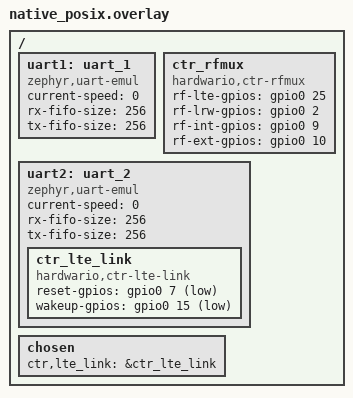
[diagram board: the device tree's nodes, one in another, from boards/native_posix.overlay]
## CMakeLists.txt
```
cmake_minimum_required(VERSION 3.20.0)

find_package(Zephyr REQUIRED HINTS $ENV{ZEPHYR_BASE})
project(test)

add_compile_definitions(CONFIG_CTR_RFMUX_LOG_LEVEL=4)
add_compile_definitions(CONFIG_CTR_LTE_LINK_LOG_LEVEL=3)

include_directories(${CMAKE_CURRENT_SOURCE_DIR}/../../../subsys/ctr_lte_v2)

target_sources(app PRIVATE src/mock_ctr_rfmux.c)
target_sources(app PRIVATE src/mock_ctr_lte_link.c)
target_sources(app PRIVATE src/mock_ctr_rtc.c)
target_sources(app PRIVATE src/mock_ctr_info.c)

target_sources_ifdef(CONFIG_TEST_FEATURE_PARSING app PRIVATE src/test_parse.c)
target_sources_ifdef(CONFIG_TEST_FEATURE_PARSING app PRIVATE src/test_state.c)
target_sources_ifdef(CONFIG_TEST_FEATURE_PARSING app PRIVATE src/test_str.c)
target_sources_ifdef(CONFIG_TEST_FEATURE_PARSING app PRIVATE src/test_fmt_duration.c)

if(CONFIG_TEST_FEATURE_PARSING AND CONFIG_CTR_LTE_V2_SCAN)
  target_sources(app PRIVATE src/test_parse_scan.c)
endif()

target_sources_ifdef(CONFIG_TEST_FEATURE_STACK app PRIVATE src/test_stack.c)
target_sources_ifdef(CONFIG_TEST_FEATURE_TXN app PRIVATE src/test_txn.c)
target_sources_ifdef(CONFIG_TEST_FEATURE_SCAN app PRIVATE src/test_scan.c)

if(CONFIG_TEST_FEATURE_STACK OR CONFIG_TEST_FEATURE_TXN OR CONFIG_TEST_FEATURE_SCAN)
  target_sources(app PRIVATE src/stack.c)
endif()

# The 'lte' shell commands, without CONFIG_CTR_SHELL (it selects the RTT backend)
if(CONFIG_TEST_FEATURE_TXN OR CONFIG_TEST_FEATURE_SCAN)
  target_sources(app PRIVATE ${CMAKE_CURRENT_SOURCE_DIR}/../../../subsys/ctr_lte_v2/ctr_lte_v2_shell.c)
endif()
```

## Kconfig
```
#
# Copyright (c) 2023 HARDWARIO a.s.
#
# SPDX-License-Identifier: LicenseRef-HARDWARIO-5-Clause
#

menu "Test Features"

config TEST_FEATURE_PARSING
	bool "TEST_FEATURE_PARSING"
	default n

config TEST_FEATURE_STACK
	bool "TEST_FEATURE_PARSING"
	default n
	select CTR_LTE_V2_GNSS

config TEST_FEATURE_STACK_OVERRIDES_CONFIG
	bool "TEST_FEATURE_STACK"
	default n
	select CTR_LTE_V2_GNSS
	select TEST_FEATURE_STACK

config TEST_FEATURE_STACK_FPLMN_ERASE_FAILS
	bool "TEST_FEATURE_STACK_FPLMN_ERASE_FAILS"
	default n
	select TEST_FEATURE_STACK
	help
	  The SIM holds forbidden networks and refuses to erase them; the
	  attach must go on anyway.

config TEST_FEATURE_TXN
	bool "TEST_FEATURE_TXN"
	default n
	select CTR_LTE_V2_GNSS
	help
	  A send_recv transaction scenario; each runs in a configuration of its
	  own.

config TEST_FEATURE_TXN_GIVE_UP_IN_RECV
	bool "TEST_FEATURE_TXN_GIVE_UP_IN_RECV"
	select TEST_FEATURE_TXN

config TEST_FEATURE_TXN_GIVE_UP_IN_ATTACH
	bool "TEST_FEATURE_TXN_GIVE_UP_IN_ATTACH"
	select TEST_FEATURE_TXN

config TEST_FEATURE_TXN_GIVE_UP_IN_ERROR
	bool "TEST_FEATURE_TXN_GIVE_UP_IN_ERROR"
	select TEST_FEATURE_TXN

config TEST_FEATURE_TXN_GIVE_UP_IN_SEND
	bool "TEST_FEATURE_TXN_GIVE_UP_IN_SEND"
	select TEST_FEATURE_TXN

config TEST_FEATURE_TXN_GIVE_UP_IN_XSEND
	bool "TEST_FEATURE_TXN_GIVE_UP_IN_XSEND"
	select TEST_FEATURE_TXN

config TEST_FEATURE_TXN_LOCK_BUSY
	bool "TEST_FEATURE_TXN_LOCK_BUSY"
	select TEST_FEATURE_TXN

config TEST_FEATURE_TXN_CSCON_AGAIN_IN_RECV
	bool "TEST_FEATURE_TXN_CSCON_AGAIN_IN_RECV"
	select TEST_FEATURE_TXN

config TEST_FEATURE_TXN_CSCON_1_0_IN_SEND
	bool "TEST_FEATURE_TXN_CSCON_1_0_IN_SEND"
	select TEST_FEATURE_TXN

config TEST_FEATURE_TXN_RECONNECT_IN_RECV
	bool "TEST_FEATURE_TXN_RECONNECT_IN_RECV"
	select TEST_FEATURE_TXN

config TEST_FEATURE_TXN_RECONNECT_IN_ERROR
	bool "TEST_FEATURE_TXN_RECONNECT_IN_ERROR"
	select TEST_FEATURE_TXN

config TEST_FEATURE_TXN_RECV_NO_DATA
	bool "TEST_FEATURE_TXN_RECV_NO_DATA"
	select TEST_FEATURE_TXN

config TEST_FEATURE_TXN_RECV_FAIL
	bool "TEST_FEATURE_TXN_RECV_FAIL"
	select TEST_FEATURE_TXN

config TEST_FEATURE_TXN_ERROR_NO_SOCKET
	bool "TEST_FEATURE_TXN_ERROR_NO_SOCKET"
	select TEST_FEATURE_TXN

config TEST_FEATURE_TXN_DISABLED
	bool "TEST_FEATURE_TXN_DISABLED"
	select TEST_FEATURE_TXN

config TEST_FEATURE_TXN_NO_CSCON
	bool "TEST_FEATURE_TXN_NO_CSCON"
	select TEST_FEATURE_TXN

config TEST_FEATURE_TXN_CSCON_TIMER
	bool "TEST_FEATURE_TXN_CSCON_TIMER"
	select TEST_FEATURE_TXN

config TEST_FEATURE_TXN_CSCON_0_IN_SEND
	bool "TEST_FEATURE_TXN_CSCON_0_IN_SEND"
	select TEST_FEATURE_TXN

config TEST_FEATURE_TXN_ERROR_IN_SEND
	bool "TEST_FEATURE_TXN_ERROR_IN_SEND"
	select TEST_FEATURE_TXN

config TEST_FEATURE_TXN_REATTACH_IN_SEND
	bool "TEST_FEATURE_TXN_REATTACH_IN_SEND"
	select TEST_FEATURE_TXN

config TEST_FEATURE_TXN_DEREGISTERED_IN_READY
	bool "TEST_FEATURE_TXN_DEREGISTERED_IN_READY"
	select TEST_FEATURE_TXN

config TEST_FEATURE_TXN_CALLBACKS
	bool "TEST_FEATURE_TXN_CALLBACKS"
	select TEST_FEATURE_TXN

config TEST_FEATURE_TXN_NO_PSM_CFUN4
	bool "TEST_FEATURE_TXN_NO_PSM_CFUN4"
	select TEST_FEATURE_TXN

config TEST_FEATURE_SCAN
	bool "TEST_FEATURE_SCAN"
	default n
	select CTR_LTE_V2_SCAN
	select CTR_LTE_V2_GNSS
	help
	  A scenario of the neighbour cell measurement or of the network scan;
	  each runs in a configuration of its own.

config TEST_FEATURE_SCAN_NCELLMEAS
	bool "TEST_FEATURE_SCAN_NCELLMEAS"
	select TEST_FEATURE_SCAN

config TEST_FEATURE_SCAN_NCELLMEAS_FAIL
	bool "TEST_FEATURE_SCAN_NCELLMEAS_FAIL"
	select TEST_FEATURE_SCAN

config TEST_FEATURE_SCAN_NCELLMEAS_NO_PSM
	bool "TEST_FEATURE_SCAN_NCELLMEAS_NO_PSM"
	select TEST_FEATURE_SCAN

config TEST_FEATURE_SCAN_NCELLMEAS_FROM_SLEEP
	bool "TEST_FEATURE_SCAN_NCELLMEAS_FROM_SLEEP"
	select TEST_FEATURE_SCAN

config TEST_FEATURE_SCAN_NCELLMEAS_CANCEL
	bool "TEST_FEATURE_SCAN_NCELLMEAS_CANCEL"
	select TEST_FEATURE_SCAN

config TEST_FEATURE_SCAN_LTE_M
	bool
	help
	  The scan runs in LTE-M only ('lte config mode lte-m', as the U1).

config TEST_FEATURE_SCAN_NB_IOT
	bool
	help
	  The scan runs in NB-IoT only ('lte config mode nb-iot', as the board with PSM).

config TEST_FEATURE_SCAN_SCAN_BOTH
	bool "TEST_FEATURE_SCAN_SCAN_BOTH"
	select TEST_FEATURE_SCAN

config TEST_FEATURE_SCAN_SCAN_ONE_RAT
	bool "TEST_FEATURE_SCAN_SCAN_ONE_RAT"
	select TEST_FEATURE_SCAN
	select TEST_FEATURE_SCAN_LTE_M

config TEST_FEATURE_SCAN_SCAN_TIMEOUTS
	bool "TEST_FEATURE_SCAN_SCAN_TIMEOUTS"
	select TEST_FEATURE_SCAN
	select TEST_FEATURE_SCAN_LTE_M

config TEST_FEATURE_SCAN_SCAN_COPS_TIMEOUT
	bool "TEST_FEATURE_SCAN_SCAN_COPS_TIMEOUT"
	select TEST_FEATURE_SCAN

config TEST_FEATURE_SCAN_SCAN_COPS_CME
	bool "TEST_FEATURE_SCAN_SCAN_COPS_CME"
	select TEST_FEATURE_SCAN

config TEST_FEATURE_SCAN_SCAN_STEP_FAIL
	bool "TEST_FEATURE_SCAN_SCAN_STEP_FAIL"
	select TEST_FEATURE_SCAN

config TEST_FEATURE_SCAN_SCAN_SEND
	bool "TEST_FEATURE_SCAN_SCAN_SEND"
	select TEST_FEATURE_SCAN
	select TEST_FEATURE_SCAN_NB_IOT

config TEST_FEATURE_SCAN_SCAN_SEND_CFUN4
	bool "TEST_FEATURE_SCAN_SCAN_SEND_CFUN4"
	select TEST_FEATURE_SCAN
	select TEST_FEATURE_SCAN_LTE_M

config TEST_FEATURE_SCAN_SCAN_SEND_AFTER
	bool "TEST_FEATURE_SCAN_SCAN_SEND_AFTER"
	select TEST_FEATURE_SCAN
	select TEST_FEATURE_SCAN_LTE_M

config TEST_FEATURE_SCAN_SCAN_RECONNECT
	bool "TEST_FEATURE_SCAN_SCAN_RECONNECT"
	select TEST_FEATURE_SCAN

config TEST_FEATURE_SCAN_SCAN_IN_ATTACH
	bool "TEST_FEATURE_SCAN_SCAN_IN_ATTACH"
	select TEST_FEATURE_SCAN
	select TEST_FEATURE_SCAN_LTE_M

config TEST_FEATURE_SCAN_SCAN_IN_RETRY_DELAY
	bool "TEST_FEATURE_SCAN_SCAN_IN_RETRY_DELAY"
	select TEST_FEATURE_SCAN
	select TEST_FEATURE_SCAN_NB_IOT

config TEST_FEATURE_SCAN_SCAN_IN_GNSS
	bool "TEST_FEATURE_SCAN_SCAN_IN_GNSS"
	select TEST_FEATURE_SCAN
	select TEST_FEATURE_SCAN_NB_IOT

config TEST_FEATURE_SCAN_SCAN_IN_GNSS_NO_PSM
	bool "TEST_FEATURE_SCAN_SCAN_IN_GNSS_NO_PSM"
	select TEST_FEATURE_SCAN
	select TEST_FEATURE_SCAN_LTE_M

config TEST_FEATURE_SCAN_SCAN_RESET_LOOP
	bool "TEST_FEATURE_SCAN_SCAN_RESET_LOOP"
	select TEST_FEATURE_SCAN
	select TEST_FEATURE_SCAN_LTE_M

config TEST_FEATURE_SCAN_SCAN_MODES
	bool "TEST_FEATURE_SCAN_SCAN_MODES"
	select TEST_FEATURE_SCAN

config CTR_LTE_V2_DEFAULT_MODE
	string "LTE Mode for CTR_LTE_V2"
	default "lte-m" if TEST_FEATURE_SCAN_LTE_M
	default "nb-iot" if TEST_FEATURE_SCAN_NB_IOT

config CTR_LTE_V2_DEFAULT_BANDS
	string "LTE Bands for CTR_LTE_V2"
	default "2,4,5,8,12,13,17,18,19,20,25,26,28,66" if TEST_FEATURE_STACK_OVERRIDES_CONFIG

config CTR_LTE_V2_DEFAULT_NETWORK
	string "Default Network for CTR_LTE_V2"
	default "23003" if TEST_FEATURE_STACK_OVERRIDES_CONFIG

config CTR_LTE_V2_DEFAULT_APN
	string "Default APN for CTR_LTE_V2"
	default "hardwario" if TEST_FEATURE_STACK_OVERRIDES_CONFIG

config CTR_LTE_V2_DEFAULT_ADDR
	string "Default Address for CTR_LTE_V2"
	default "46.101.214.168" if TEST_FEATURE_STACK_OVERRIDES_CONFIG

endmenu

#Include Zephyr's Kconfig
source "Kconfig"
```

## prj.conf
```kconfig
CONFIG_ZTEST=y
CONFIG_HEAP_MEM_POOL_SIZE=256
CONFIG_MAIN_STACK_SIZE=2048

CONFIG_LOG=y
CONFIG_LOG_FUNC_NAME_PREFIX_ERR=y
CONFIG_LOG_FUNC_NAME_PREFIX_WRN=y
CONFIG_LOG_FUNC_NAME_PREFIX_INF=y
CONFIG_LOG_FUNC_NAME_PREFIX_DBG=y

CONFIG_EVENTS=y

CONFIG_CTR_BUF=y
CONFIG_CTR_UTIL=y
CONFIG_CTR_CONFIG=y

CONFIG_CTR_LTE_V2=y
CONFIG_CTR_LTE_V2_LOG_LEVEL_DBG=y

CONFIG_SETTINGS=y

CONFIG_SHELL=y
CONFIG_SHELL_LOG_BACKEND=n
CONFIG_SHELL_BACKEND_SERIAL=y
CONFIG_SHELL_BACKEND_DUMMY=y
CONFIG_SHELL_CMD_BUFF_SIZE=90
CONFIG_SHELL_BACKEND_DUMMY_BUF_SIZE=4096

CONFIG_CBPRINTF_FP_SUPPORT=y

CONFIG_TEST_USERSPACE=y
CONFIG_GPIO=n
CONFIG_SERIAL=y
CONFIG_UART_NATIVE_PTY_0_ON_STDINOUT=y

CONFIG_HEAP_MEM_POOL_SIZE=8192

CONFIG_PM_DEVICE=y
CONFIG_REQUIRES_FULL_LIBC=y
CONFIG_RING_BUFFER=y

CONFIG_THREAD_NAME=y
CONFIG_THREAD_MONITOR=y
```

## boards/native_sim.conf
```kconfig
CONFIG_FLASH_SIMULATOR=y
CONFIG_FLASH=y
CONFIG_FLASH_MAP=y
```

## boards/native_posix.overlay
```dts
/ {

	uart1: uart_1 {
		compatible = "zephyr,uart-emul";
		status = "okay";
		current-speed = <0>;
		rx-fifo-size = <256>;
		tx-fifo-size = <256>;
	};

	ctr_rfmux: ctr_rfmux {
		compatible = "hardwario,ctr-rfmux";
		rf-lte-gpios = <&gpio0 25 GPIO_ACTIVE_HIGH>;
		rf-lrw-gpios = <&gpio0 2 GPIO_ACTIVE_HIGH>;
		rf-int-gpios = <&gpio0 9 GPIO_ACTIVE_HIGH>;
		rf-ext-gpios = <&gpio0 10 GPIO_ACTIVE_HIGH>;
	};

	uart2: uart_2 {
		compatible = "zephyr,uart-emul";
		status = "okay";
		current-speed = <0>;
		rx-fifo-size = <256>;
		tx-fifo-size = <256>;

		ctr_lte_link: ctr_lte_link {
			compatible = "hardwario,ctr-lte-link";
			status = "okay";
			reset-gpios = <&gpio0 7 (GPIO_ACTIVE_LOW | GPIO_OPEN_DRAIN)>;
			wakeup-gpios = <&gpio0 15 (GPIO_ACTIVE_LOW | GPIO_OPEN_DRAIN)>;
		};
	};
};

/ {
	chosen {
		ctr,lte_link = &ctr_lte_link;
	};
};
```

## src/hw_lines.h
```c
/** @file
 *  @brief Modem lines captured on hardware (CHESTER-U1, mfw 1.3.6, SLM 2.5.2), shared by tests
 *
 *  HW_* lines are verbatim captures, SYN_* lines are synthetic (the comment says why).
 */

#ifndef CHESTER_TESTS_CTR_LTE_V2_HW_LINES_H_
#define CHESTER_TESTS_CTR_LTE_V2_HW_LINES_H_

/* %NCELLMEAS=5,7 after the registration, in the RRC idle: 4 cells in 3 PLMNs */
#define HW_NCELLMEAS_REGISTERED                                                                    \
	"0,\"074FEB50\",\"23002\",\"05F2\",31,941054,6300,488,67,17,1139290,1,0,"                  \
	"\"074FEB51\",\"23002\",\"05F2\",65535,0,6300,339,65,12,1139290,0,0,"                      \
	"\"074FEB0C\",\"23001\",\"3866\",65535,0,6200,14,66,14,1139326,0,0,"                       \
	"\"000AE5CA\",\"23003\",\"8DCC\",65535,0,3544,135,75,32,1139335,0,0"

/* %NCELLMEAS=5,7 while searching the network (+CEREG: 2): the serving cell and a neighbour */
#define HW_NCELLMEAS_SEARCHING                                                                     \
	"0,\"074FEB50\",\"23002\",\"05F2\",17,80345,6300,488,68,19,73670,1,1,6300,339,64,12,0"

/* %NCELLMEAS=5,7 with the RRC connection still open (before +CSCON: 0) */
#define HW_NCELLMEAS_CONNECTED                                                                     \
	"0,\"074FEB50\",\"23002\",\"05F2\",15,12872307,6300,488,67,15,12865064,1,1,6300,339,66,"   \
	"14,0"

/* The URC sent at once by %NCELLMEASSTOP during a measurement: the 3 cells found so far */
#define HW_NCELLMEAS_STOPPED                                                                       \
	"0,\"074FEB50\",\"23002\",\"05F2\",15,12887435,6300,488,67,21,12913708,1,0,"               \
	"\"074FEB51\",\"23002\",\"05F2\",65535,0,6300,339,66,19,12913708,0,0,"                     \
	"\"000AE5CA\",\"23003\",\"8DCC\",65535,0,3544,135,75,29,12913846,0,0"

/* %NCELLMEAS=5,7 camped on NB-IoT without a registration: one cell */
#define HW_NCELLMEAS_NBIOT_CAMPED                                                                  \
	"0,\"074FEBAC\",\"23001\",\"28B4\",0,13115210,6247,14,73,21,13116648,1,0"

/* %NCELLMEAS=5,7 in PSM (the board with the SIM of 23003, gate 3A, A1): after 118 s, three
 * cells and none of them serving */
#define HW_PSM_NCELLMEAS                                                                           \
	"0,\"000AE520\",\"23003\",\"B4DC\",65535,0,6447,135,88,28,647446,0,0,"                     \
	"\"074FEB56\",\"23002\",\"2D02\",65535,0,6348,339,72,26,647523,0,0,"                       \
	"\"074FEBAC\",\"23001\",\"28B4\",65535,0,6247,14,77,28,647603,0,0"

/* The URC sent at once by %NCELLMEASSTOP in PSM (gate 3A, A2): the one cell found so far */
#define HW_PSM_NCELLMEAS_STOPPED                                                                   \
	"0,\"000AE520\",\"23003\",\"B4DC\",65535,0,6447,135,88,29,658953,0,0"

/* AT+COPS=? on LTE-M after the registration (U1): the camped RAT only, no names */
#define HW_COPS_LIST "(1,\"\",\"\",\"23001\",7),(1,\"\",\"\",\"23003\",7),(2,\"\",\"\",\"23002\",7)"

/* AT+COPS=? on NB-IoT, camped without a registration (U1); stat 2 is the camped network */
#define HW_COPS_NBIOT_CAMPED                                                                       \
	"(1,\"\",\"\",\"23003\",9),(2,\"\",\"\",\"23001\",9),(1,\"\",\"\",\"23002\",9)"

/* AT+COPS=? on NB-IoT in PSM (the board with the SIM of 23003) */
#define HW_COPS_PSM_NBIOT                                                                          \
	"(2,\"\",\"\",\"23003\",9),(1,\"\",\"\",\"23002\",9),(1,\"\",\"\",\"23001\",9)"

/* +CEREG on NB-IoT, camped without a registration (U1) */
#define HW_CEREG_NBIOT_CAMPED "+CEREG: 2,\"2D02\",\"074FEB55\",9"

/* The registration rejected on NB-IoT (the board with PSM, network forced to 23002, gate 3B): the
 * reject is stat 2 with the EMM cause 11, 6.6 s after the CFUN=1 */
#define HW_REJECT_CEREG_SEARCH "+CEREG: 2,\"2D02\",\"074FEB56\",9"
#define HW_REJECT_CEREG        "+CEREG: 2,\"2D02\",\"074FEB56\",9,0,11"

/* %NCELLMEAS=5,7 after the reject (B1, after 126 s): the rejecting network serves */
#define HW_REJECT_NCELLMEAS                                                                        \
	"0,\"074FEB56\",\"23002\",\"2D02\",0,964058,6348,339,71,25,1097250,1,0,"                   \
	"\"000AE520\",\"23003\",\"B4DC\",65535,0,6447,135,85,22,1097285,0,0,"                      \
	"\"074FEBAC\",\"23001\",\"28B4\",65535,0,6247,14,77,27,1097323,0,0"

/* AT+COPS=? after the reject (B2, after 92 s): 23002 forbidden */
#define HW_REJECT_COPS                                                                             \
	"(3,\"\",\"\",\"23002\",9),(1,\"\",\"\",\"23001\",9),(1,\"\",\"\",\"23003\",9)"

/* The registration of LTE-M reported during its AT+COPS=? (not seen on the modem): a REGISTERED
 * counts only in the registration step */
#define SYN_CEREG_STALE_LTEM "+CEREG: 5,\"05F2\",\"074FEB50\",7,,,\"11100000\",\"11100000\""

/* 12 networks with names, over 500 B (the modem sends 1024 B at most), no 23003: the list is
 * longer than the 10 networks we keep and than any buffer a parser might copy it into */
#define SYN_COPS_LONG                                                                              \
	"(1,\"Telekom Long Name 1\",\"TLN1\",\"26201\",7),"                                        \
	"(1,\"Telekom Long Name 2\",\"TLN2\",\"26202\",7),"                                        \
	"(1,\"Telekom Long Name 3\",\"TLN3\",\"26203\",7),"                                        \
	"(1,\"Telekom Long Name 4\",\"TLN4\",\"26204\",7),"                                        \
	"(1,\"Telekom Long Name 5\",\"TLN5\",\"26205\",7),"                                        \
	"(1,\"Telekom Long Name 6\",\"TLN6\",\"26206\",7),"                                        \
	"(1,\"Telekom Long Name 7\",\"TLN7\",\"26207\",7),"                                        \
	"(1,\"Telekom Long Name 8\",\"TLN8\",\"26208\",7),"                                        \
	"(1,\"Telekom Long Name 9\",\"TLN9\",\"26209\",7),"                                        \
	"(1,\"Telekom Long Name 10\",\"TLN10\",\"26210\",7),"                                      \
	"(1,\"Telekom Long Name 11\",\"TLN11\",\"26211\",7),"                                      \
	"(2,\"Telekom Long Name 12\",\"TLN12\",\"26212\",7),,(0,1,2,3,4),(0,1,2)"

/* A list without the closing parenthesis of the last network */
#define SYN_COPS_BAD "(1,\"\",\"\",\"23001\",7),(1,\"\",\"\",\"23003\",7"

/* A neighbour (earfcn, pci, rsrp, rsrq, time_diff) to build lines with 10 and more of them */
#define SYN_NCELL ",6300,339,64,12,0"

/* The first cell of HW_NCELLMEAS_REGISTERED followed by a second one cut after the PLMN */
#define SYN_NCELLMEAS_CUT                                                                          \
	"0,\"074FEB50\",\"23002\",\"05F2\",31,941054,6300,488,67,17,1139290,1,0,"                  \
	"\"074FEB51\",\"23002\""

#endif /* CHESTER_TESTS_CTR_LTE_V2_HW_LINES_H_ */
```

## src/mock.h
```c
#ifndef TESTS_SUBSYS_CTR_LTE_V2_SRC_MOCK_H_
#define TESTS_SUBSYS_CTR_LTE_V2_SRC_MOCK_H_

/* Zephyr includes */
#include <zephyr/kernel.h>

/* Standard includes */
#include <errno.h>
#include <stdarg.h>
#include <stdbool.h>
#include <stddef.h>
#include <stdint.h>
#include <stdio.h>
#include <string.h>

/* The longest script the mock keeps the times of */
#define MOCK_LINK_MAX_ITEMS 512

/* The resets of a script the mock keeps the places of */
#define MOCK_LINK_MAX_RESETS 8

struct mock_link_item {
	const char *tx;
	const char *rx;
	const char *rx2;
	int delay_ms;
};

typedef char **list;

/* Load a script of AT lines: an item with tx expects that line from the FSM and answers with rx
 * and rx2, an item without tx is a URC sent delay_ms after the previous item (or after the
 * start). A line the script does not expect at that point (also after its end) is a violation. */
void mock_ctr_lte_link_start(struct mock_link_item *items, size_t count);

/* When the item of the loaded script was handled, in k_uptime_get() ms: the FSM sent its line (tx)
 * or the mock sent the URC. -1 for an item not reached yet and for an index past the script. */
int64_t mock_ctr_lte_link_tx_time(size_t index);

/* Assert, from the test thread, that the script ran to its end without a violation */
void mock_ctr_lte_link_assert_done(void);

/* The resets of the modem so far (the reset is not a line of the script) */
int mock_ctr_lte_link_reset_count(void);

/* The next count wake-ups get no "Ready": the modem does not answer after a reset */
void mock_ctr_lte_link_drop_ready(int count);

/* Where the n-th reset (from 0) since mock_ctr_lte_link_start() came: the index of the script item
 * after it. -1 for a reset not made, or not followed by a wake-up before that item (the modem boots
 * on the wake-up after its reset) */
int mock_ctr_lte_link_reset_item(int n);

#endif
```

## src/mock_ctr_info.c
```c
#include <chester/ctr_info.h>

int ctr_info_get_vendor_name(char **vendor_name)
{
	static char name[] = "HARDWARIO";
	*vendor_name = name;
	return 0;
}

int ctr_info_get_product_name(char **product_name)
{
	static char name[] = "CHESTER-M";
	*product_name = name;
	return 0;
}

int ctr_info_get_hw_variant(char **hw_variant)
{
	static char variant[] = "CGLS";
	*hw_variant = variant;
	return 0;
}
int ctr_info_get_hw_revision(char **hw_revision)
{
	static char revision[] = "R3.2";
	*hw_revision = revision;
	return 0;
}

int ctr_info_get_fw_bundle(char **fw_bundle)
{
	static char bundle[] = "com.hardwario.mockup-app";
	*fw_bundle = bundle;
	return 0;
}

int ctr_info_get_fw_name(char **fw_name)
{
	static char name[] = "mockup-app";
	*fw_name = name;
	return 0;
}

int ctr_info_get_fw_version(char **fw_version)
{
	static char version[] = "v0.0.1";
	*fw_version = version;
	return 0;
}

int ctr_info_get_serial_number_uint32(uint32_t *serial_number)
{
	*serial_number = 2159017985;
	return 0;
}

int ctr_info_get_claim_token(char **claim_token)
{
	static char token[] = "98a8856ba6534bd5212176b22f3acbb3";
	*claim_token = token;
	return 0;
}

int ctr_info_get_ble_passkey(char **ble_passkey)
{
	static char passkey[] = "654123";
	*ble_passkey = passkey;
	return 0;
}

int ctr_info_get_product_family(enum ctr_info_product_family *product_family)
{
	*product_family = CTR_INFO_PRODUCT_FAMILY_CHESTER_M;
	return 0;
}
```

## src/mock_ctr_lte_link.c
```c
/*
 * Copyright (c) 2023 HARDWARIO a.s.
 *
 * SPDX-License-Identifier: LicenseRef-HARDWARIO-5-Clause
 */

#include "mock.h"
/* CHESTER includes */
#include <chester/drivers/ctr_lte_link.h>

/* Zephyr includes */
#include <zephyr/device.h>
#include <zephyr/devicetree.h>
#include <zephyr/kernel.h>
#include <zephyr/logging/log.h>
#include <zephyr/ztest.h>

/* Standard includes */
#include <errno.h>
#include <stdarg.h>
#include <stdbool.h>
#include <stddef.h>
#include <stdint.h>
#include <stdio.h>
#include <string.h>

#define DT_DRV_COMPAT hardwario_ctr_lte_link

LOG_MODULE_REGISTER(ctr_lte_link, LOG_LEVEL_INF);

#define RESET_DELAY   K_MSEC(100)
#define RESET_PAUSE   K_SECONDS(3)
#define WAKE_UP_DELAY K_MSEC(100)
#define WAKE_UP_PAUSE K_MSEC(100)
#define TX_GUARD_TIME K_MSEC(10)

#define TX_LINE_SUFFIX "\r\n"

#define TX_LINE_BUF_SIZE 1024
#define RX_LINE_BUF_SIZE 1024
#define RX_HEAP_MEM_SIZE 4096
#define RX_PIPE_BUF_SIZE 512
#define STACK_SIZE       1024
#define WORKQ_PRIORITY   K_PRIO_COOP(7)

#define VIOLATION_BUF_SIZE 256

struct ctr_lte_link_data {
	bool enabled;
	struct k_mutex lock;
	atomic_t in_dialog;
	atomic_t in_data_mode;
	atomic_t stop_request;
	char rx_line_buf[RX_LINE_BUF_SIZE];
	char tx_line_buf[TX_LINE_BUF_SIZE];
	const struct device *dev;
	ctr_lte_link_user_cb user_cb;
	void *user_data;
	struct k_work event_dispatch_work;
	struct k_work_delayable urc_dispatch_work;

	struct k_work_q workq;
	K_KERNEL_STACK_MEMBER(workq_stack, STACK_SIZE);
	struct k_fifo rx_fifo;
	struct k_heap rx_heap;
	uint8_t rx_heap_mem[RX_HEAP_MEM_SIZE];
	k_timepoint_t tx_timepoint;

	/* The script state is shared by the FSM thread (TX lines) and the mock work queue (URCs);
	 * script_lock guards it, so the test thread can read it while the FSM sits in a dialog */
	struct k_spinlock script_lock;
	struct mock_link_item *items;
	size_t items_count;
	size_t items_index;
	int64_t item_time[MOCK_LINK_MAX_ITEMS]; /* k_uptime_get() of each item, -1 before it */
	/* The resets of the script: the next item at each, and at the first wake-up after it */
	int resets;
	int reset_item[MOCK_LINK_MAX_RESETS];
	int wake_up_item[MOCK_LINK_MAX_RESETS];
	int violations;
	char violation[VIOLATION_BUF_SIZE];
	/* mock_ctr_lte_link_model_subscriptions() */
	bool model_subscriptions;
	bool cereg_subscribed;
	bool cscon_subscribed;

	const char *pending_rx_data;
	size_t pending_rx_data_len;
};

static inline struct ctr_lte_link_data *get_data(const struct device *dev)
{
	return dev->data;
}

/* Record a departure from the script. Asserting here would fail the test from the FSM thread or
 * from the mock work queue, so the first violation is kept for mock_ctr_lte_link_assert_done(),
 * which asserts from the test thread. The caller holds script_lock. */
static void record_violation(struct ctr_lte_link_data *data, const char *format, ...)
{
	char msg[VIOLATION_BUF_SIZE];
	va_list ap;

	va_start(ap, format);
	vsnprintf(msg, sizeof(msg), format, ap);
	va_end(ap);

	LOG_ERR("Script violation: %s", msg);

	if (!data->violations++) {
		strcpy(data->violation, msg);
	}
}

static int ctr_lte_link_set_callback_(const struct device *dev, ctr_lte_link_user_cb user_cb,
				      void *user_data)
{

	k_mutex_lock(&get_data(dev)->lock, K_FOREVER);

	get_data(dev)->user_cb = user_cb;
	get_data(dev)->user_data = user_data;

	k_mutex_unlock(&get_data(dev)->lock);

	return 0;
}

static void ctr_lte_link_lock_(const struct device *dev)
{
	LOG_DBG("Lock");
	k_mutex_lock(&get_data(dev)->lock, K_FOREVER);
}

static void ctr_lte_link_unlock_(const struct device *dev)
{
	LOG_DBG("Unlock");
	k_mutex_unlock(&get_data(dev)->lock);
}

/* The resets so far, and the wake-ups left without a "Ready" */
static atomic_t m_reset_count;
static atomic_t m_ready_drop;

static int ctr_lte_link_reset_(const struct device *dev)
{

	struct ctr_lte_link_data *data = get_data(dev);

	LOG_DBG("Reset");
	atomic_inc(&m_reset_count);

	k_spinlock_key_t key = k_spin_lock(&data->script_lock);

	if (data->resets < MOCK_LINK_MAX_RESETS) {
		data->reset_item[data->resets] = data->items_index;
		data->wake_up_item[data->resets] = -1;
	}
	data->resets++;
	data->cereg_subscribed = false;
	data->cscon_subscribed = false;

	k_spin_unlock(&data->script_lock, key);

	k_sleep(RESET_DELAY);
	// k_sleep(RESET_PAUSE);
	return 0;
}

static int rx(const struct device *dev, const char line[])
{
	size_t len = strlen(line);

	struct ctr_lte_link_data *data = get_data(dev);

	char *p = k_heap_alloc(&data->rx_heap, len + 1, K_NO_WAIT);
	if (!p) {
		LOG_ERR("Call `k_heap_alloc` failed");
		if (data->user_cb) {
			data->user_cb(data->dev, CTR_LTE_LINK_EVENT_RX_LOSS, data->user_data);
		}

		return -ENOMEM;
	}

	LOG_DBG("Allocated from heap: %p - %u byte(s)", (void *)p, len + 1);

	strcpy(p, line);

	int ret = k_fifo_alloc_put(&data->rx_fifo, p);
	if (ret) {
		LOG_ERR("Call `k_fifo_alloc_put` failed: %d", ret);
		k_heap_free(&data->rx_heap, p);
		LOG_DBG("Released from heap: %p", (void *)p);
		return -ENOMEM;
	}

	if (data->user_cb && !atomic_get(&data->in_dialog)) {
		k_work_submit_to_queue(&data->workq, &data->event_dispatch_work);
	}

	return 0;
}

static void event_dispatch_work_handler(struct k_work *work)
{
	struct ctr_lte_link_data *const data =
		CONTAINER_OF(work, struct ctr_lte_link_data, event_dispatch_work);

	if (data->user_cb) {
		data->user_cb(data->dev, CTR_LTE_LINK_EVENT_RX_LINE, data->user_data);
	}
}

/* The subscriptions after a line of the script; one refused changes nothing. The caller holds
 * script_lock */
static void update_subscriptions(struct ctr_lte_link_data *data, const struct mock_link_item *item)
{
	const char *line = item->tx;

	if (!item->rx || strcmp(item->rx, "OK")) {
		return;
	}

	if (!strcmp(line, "AT+CFUN=0")) {
		data->cereg_subscribed = false;
		data->cscon_subscribed = false;
	} else if (!strcmp(line, "AT+CEREG=5")) {
		data->cereg_subscribed = true;
	} else if (!strcmp(line, "AT+CSCON=1")) {
		data->cscon_subscribed = true;
	}
}

/* A URC the modem does not send for want of its subscription; the caller holds script_lock */
static bool urc_unsubscribed(struct ctr_lte_link_data *data, const char *line)
{
	if (!data->model_subscriptions || !line) {
		return false;
	}

	return (!strncmp(line, "+CEREG: ", 8) && !data->cereg_subscribed) ||
	       (!strncmp(line, "+CSCON: ", 8) && !data->cscon_subscribed);
}

/* Schedule the next item if it is a URC; the caller holds script_lock */
static void schedule_next_urc(struct ctr_lte_link_data *data)
{
	if (data->items_index < data->items_count) {
		const struct mock_link_item *item = &data->items[data->items_index];
		if (item->tx == NULL) {
			k_work_schedule(&data->urc_dispatch_work, K_MSEC(item->delay_ms));
		}
	}
}

static void urc_dispatch_work_handler(struct k_work *work)
{
	struct ctr_lte_link_data *const data = CONTAINER_OF(
		(struct k_work_delayable *)work, struct ctr_lte_link_data, urc_dispatch_work);

	const struct mock_link_item *item = NULL;
	bool unsubscribed = false;

	k_spinlock_key_t key = k_spin_lock(&data->script_lock);

	if (data->items_index < data->items_count && data->items[data->items_index].tx == NULL) {
		data->item_time[data->items_index] = k_uptime_get();
		item = &data->items[data->items_index++];
		unsubscribed = urc_unsubscribed(data, item->rx);

		/* If URC starts with #XRECV:, store rx2 as pending data */
		if (item->rx && strncmp(item->rx, "#XRECV:", 7) == 0 && item->rx2) {
			int expected_len = 0;
			sscanf(item->rx + 7, " %d", &expected_len);
			if ((size_t)expected_len != strlen(item->rx2)) {
				record_violation(data,
						 "XRECV len mismatch: header says %d, data is %zu",
						 expected_len, strlen(item->rx2));
			}

			data->pending_rx_data = item->rx2;
			data->pending_rx_data_len = strlen(item->rx2);
		}

		schedule_next_urc(data);
	}

	k_spin_unlock(&data->script_lock, key);

	if (unsubscribed) {
		LOG_INF("Not subscribed, URC not sent: %s", item->rx);
	} else if (item && item->rx) {
		rx(data->dev, item->rx);
	}
}

static int ctr_lte_link_wake_up_(const struct device *dev)
{

	struct ctr_lte_link_data *data = get_data(dev);

	LOG_INF("Wake up");

	k_spinlock_key_t key = k_spin_lock(&data->script_lock);

	int n = data->resets - 1;
	if (n >= 0 && n < MOCK_LINK_MAX_RESETS && data->wake_up_item[n] < 0) {
		data->wake_up_item[n] = data->items_index;
	}

	k_spin_unlock(&data->script_lock, key);

	k_sleep(WAKE_UP_DELAY);
	// k_sleep(WAKE_UP_PAUSE);
	if (atomic_get(&m_ready_drop) > 0) {
		atomic_dec(&m_ready_drop);
		LOG_INF("No Ready");
		return 0;
	}
	rx(dev, "Ready");
	return 0;
}

static int ctr_lte_link_enable_uart_(const struct device *dev)
{

	LOG_DBG("Enable UART");

	k_mutex_lock(&get_data(dev)->lock, K_FOREVER);

	if (get_data(dev)->enabled) {
		k_mutex_unlock(&get_data(dev)->lock);
		return 0;
	}

	atomic_set(&get_data(dev)->in_dialog, false);
	atomic_set(&get_data(dev)->in_data_mode, false);
	atomic_set(&get_data(dev)->stop_request, false);

	get_data(dev)->enabled = true;

	k_mutex_unlock(&get_data(dev)->lock);

	return 0;
}

static int ctr_lte_link_disable_uart_(const struct device *dev)
{

	LOG_DBG("Disable UART");

	k_mutex_lock(&get_data(dev)->lock, K_FOREVER);

	if (!get_data(dev)->enabled) {
		k_mutex_unlock(&get_data(dev)->lock);
		return 0;
	}

	get_data(dev)->enabled = false;

	k_mutex_unlock(&get_data(dev)->lock);

	return 0;
}

static int ctr_lte_link_enter_data_mode_(const struct device *dev)
{
	LOG_DBG("Enter data mode");

	k_mutex_lock(&get_data(dev)->lock, K_FOREVER);

	if (!get_data(dev)->enabled) {
		k_mutex_unlock(&get_data(dev)->lock);
		return -EBUSY;
	}

	atomic_set(&get_data(dev)->in_data_mode, true);

	k_mutex_unlock(&get_data(dev)->lock);

	return 0;
}

static int ctr_lte_link_exit_data_mode_(const struct device *dev)
{
	LOG_DBG("Exit data mode");

	k_mutex_lock(&get_data(dev)->lock, K_FOREVER);

	if (!get_data(dev)->enabled) {
		k_mutex_unlock(&get_data(dev)->lock);
		return -EBUSY;
	}

	atomic_set(&get_data(dev)->in_data_mode, false);

	k_mutex_unlock(&get_data(dev)->lock);

	return 0;
}

static int ctr_lte_link_enter_dialog_(const struct device *dev)
{
	LOG_DBG("Enter dialog");

	k_mutex_lock(&get_data(dev)->lock, K_FOREVER);

	if (!get_data(dev)->enabled) {
		k_mutex_unlock(&get_data(dev)->lock);
		return -EBUSY;
	}

	atomic_set(&get_data(dev)->in_dialog, true);

	k_mutex_unlock(&get_data(dev)->lock);

	return 0;
}

static int ctr_lte_link_exit_dialog_(const struct device *dev)
{
	LOG_DBG("Exit dialog");

	k_mutex_lock(&get_data(dev)->lock, K_FOREVER);

	if (!get_data(dev)->enabled) {
		k_mutex_unlock(&get_data(dev)->lock);
		return -EBUSY;
	}

	atomic_set(&get_data(dev)->in_dialog, false);

	k_mutex_unlock(&get_data(dev)->lock);

	/* As the driver does: the URCs that came during the dialog are dispatched now */
	if (get_data(dev)->user_cb) {
		k_work_submit_to_queue(&get_data(dev)->workq, &get_data(dev)->event_dispatch_work);
	}

	return 0;
}

static int ctr_lte_link_send_line_(const struct device *dev, k_timeout_t timeout,
				   const char *format, va_list ap)
{

	struct ctr_lte_link_data *data = get_data(dev);

	k_mutex_lock(&data->lock, K_FOREVER);

	if (!data->enabled) {
		k_mutex_unlock(&data->lock);
		return -EBUSY;
	}

	if (data->in_data_mode) {
		k_mutex_unlock(&data->lock);
		return -EPERM;
	}

	// if (!sys_timepoint_expired(data->tx_timepoint)) {
	// 	k_sleep(sys_timepoint_timeout(data->tx_timepoint));
	// }

	size_t size = sizeof(data->tx_line_buf) - strlen(TX_LINE_SUFFIX);

	int ret = vsnprintf(data->tx_line_buf, size, format, ap);
	if (ret < 0) {
		LOG_ERR("Call `vsnprintf` failed: %d", ret);
		k_mutex_unlock(&data->lock);
		return -EINVAL;
	} else if (ret >= size) {
		LOG_ERR("Buffer too small");
		k_mutex_unlock(&data->lock);
		return -ENOBUFS;
	}

	LOG_INF("Send line: %s", data->tx_line_buf);

	// strcat(data->tx_line_buf, TX_LINE_SUFFIX);

	/* A line the script does not expect gets no response and is recorded as a violation */
	const struct mock_link_item *item = NULL;

	k_spinlock_key_t key = k_spin_lock(&data->script_lock);

	if (data->items_index >= data->items_count) {
		record_violation(data, "unexpected TX after the end of the script: %s",
				 data->tx_line_buf);
	} else if (data->items[data->items_index].tx == NULL) {
		record_violation(data, "unexpected TX at item %zu, expected URC %s: %s",
				 data->items_index, data->items[data->items_index].rx,
				 data->tx_line_buf);
	} else if (strcmp(data->tx_line_buf, data->items[data->items_index].tx) != 0) {
		record_violation(data, "unexpected TX at item %zu, expected %s: %s",
				 data->items_index, data->items[data->items_index].tx,
				 data->tx_line_buf);
	} else {
		data->item_time[data->items_index] = k_uptime_get();
		item = &data->items[data->items_index++];
		update_subscriptions(data, item);
	}

	k_spin_unlock(&data->script_lock, key);

	if (item) {
		if (item->rx) {
			rx(dev, item->rx);
		}
		if (item->rx2) {
			rx(dev, item->rx2);
		}

		/* Only after the response, so that a URC due at once comes after it */
		key = k_spin_lock(&data->script_lock);
		schedule_next_urc(data);
		k_spin_unlock(&data->script_lock, key);
	}

	// if (strcmp(data->tx_line_buf, "AT") == 0) {
	// 	rx(dev, "OK");
	// }
	// if (strcmp(data->tx_line_buf, "AT+CGSN=1") == 0) {
	// 	rx(dev, "+CGSN: \"351358815178345\"");
	// 	rx(dev, "OK");
	// }

	// data->tx_timepoint = sys_timepoint_calc(TX_GUARD_TIME);

	k_mutex_unlock(&data->lock);

	return 0;
}

static int ctr_lte_link_recv_line_(const struct device *dev, k_timeout_t timeout, char **line)
{
	k_mutex_lock(&get_data(dev)->lock, K_FOREVER);

	if (get_data(dev)->in_data_mode) {
		k_mutex_unlock(&get_data(dev)->lock);
		return -EPERM;
	}

	*line = k_fifo_get(&get_data(dev)->rx_fifo, timeout);
	if (*line) {
		LOG_INF("Receive line: %s", *line);
	}

	k_mutex_unlock(&get_data(dev)->lock);

	return 0;
}

static int ctr_lte_link_free_line_(const struct device *dev, char *line)
{

	k_mutex_lock(&get_data(dev)->lock, K_FOREVER);

	k_heap_free(&get_data(dev)->rx_heap, line);
	LOG_DBG("Released from heap: %p", (void *)line);

	k_mutex_unlock(&get_data(dev)->lock);

	return 0;
}

static int ctr_lte_link_send_data_(const struct device *dev, k_timeout_t timeout, const void *buf,
				   size_t len)
{

	k_mutex_lock(&get_data(dev)->lock, K_FOREVER);

	if (!get_data(dev)->enabled) {
		k_mutex_unlock(&get_data(dev)->lock);
		return -EBUSY;
	}

	if (!get_data(dev)->in_data_mode) {
		k_mutex_unlock(&get_data(dev)->lock);
		return -EPERM;
	}

	k_mutex_unlock(&get_data(dev)->lock);

	return 0;
}

static int ctr_lte_link_recv_data_(const struct device *dev, k_timeout_t timeout, void *buf,
				   size_t size, size_t *len)
{
	struct ctr_lte_link_data *data = get_data(dev);

	LOG_INF("size: %d pending: %d", size, data->pending_rx_data_len);

	k_mutex_lock(&data->lock, K_FOREVER);

	if (!data->enabled) {
		k_mutex_unlock(&data->lock);
		return -EBUSY;
	}

	if (!data->in_data_mode) {
		k_mutex_unlock(&data->lock);
		return -EPERM;
	}

	*len = 0;

	if (data->pending_rx_data && data->pending_rx_data_len > 0) {
		size_t copy_len = data->pending_rx_data_len;
		if (copy_len > size) {
			copy_len = size;
		}
		memcpy(buf, data->pending_rx_data, copy_len);
		*len = copy_len;

		data->pending_rx_data = NULL;
		data->pending_rx_data_len = 0;
		rx(dev, "OK"); // Simulate OK after XRECV data is read
	}

	k_mutex_unlock(&data->lock);

	return 0;
}

static int ctr_lte_link_drv_init(const struct device *dev)
{
	struct ctr_lte_link_data *data = get_data(dev);
	k_mutex_init(&data->lock);
	k_fifo_init(&data->rx_fifo);
	k_heap_init(&data->rx_heap, data->rx_heap_mem, RX_HEAP_MEM_SIZE);

	struct k_work_queue_config cfg = {
		.name = "ctr_lte_link_drv_workq",
	};

	k_work_queue_start(&data->workq, data->workq_stack,
			   K_THREAD_STACK_SIZEOF(data->workq_stack), WORKQ_PRIORITY, &cfg);

	k_work_init(&data->event_dispatch_work, event_dispatch_work_handler);
	k_work_init_delayable(&data->urc_dispatch_work, urc_dispatch_work_handler);
	return 0;
}

static const struct ctr_lte_link_driver_api ctr_lte_link_driver_api = {
	.set_callback = ctr_lte_link_set_callback_,
	.lock = ctr_lte_link_lock_,
	.unlock = ctr_lte_link_unlock_,
	.reset = ctr_lte_link_reset_,
	.wake_up = ctr_lte_link_wake_up_,
	.enable_uart = ctr_lte_link_enable_uart_,
	.disable_uart = ctr_lte_link_disable_uart_,
	.enter_dialog = ctr_lte_link_enter_dialog_,
	.exit_dialog = ctr_lte_link_exit_dialog_,
	.enter_data_mode = ctr_lte_link_enter_data_mode_,
	.exit_data_mode = ctr_lte_link_exit_data_mode_,
	.send_line = ctr_lte_link_send_line_,
	.recv_line = ctr_lte_link_recv_line_,
	.free_line = ctr_lte_link_free_line_,
	.send_data = ctr_lte_link_send_data_,
	.recv_data = ctr_lte_link_recv_data_,
};

#define CTR_LTE_LINK_INIT(n)                                                                       \
	static struct ctr_lte_link_data inst_##n##_data = {                                        \
		.dev = DEVICE_DT_INST_GET(n),                                                      \
	};                                                                                         \
	DEVICE_DT_INST_DEFINE(n, ctr_lte_link_drv_init, NULL, &inst_##n##_data, NULL, POST_KERNEL, \
			      CONFIG_SERIAL_INIT_PRIORITY, &ctr_lte_link_driver_api);

DT_INST_FOREACH_STATUS_OKAY(CTR_LTE_LINK_INIT)

void mock_ctr_lte_link_start(struct mock_link_item *items, size_t count)
{
	LOG_INF("Mock CTR LTE LINK start");

	const struct device *dev = DEVICE_DT_INST_GET(0);

	if (!device_is_ready(dev)) {
		LOG_ERR("Device is not ready");
		return;
	}

	struct ctr_lte_link_data *data = get_data(DEVICE_DT_INST_GET(0));

	k_work_cancel_delayable(&data->urc_dispatch_work);

	k_spinlock_key_t key = k_spin_lock(&data->script_lock);

	zassert_true(count <= MOCK_LINK_MAX_ITEMS, "a script of %zu items, the mock keeps %d",
		     count, MOCK_LINK_MAX_ITEMS);

	data->items = items;
	data->items_count = count;
	data->items_index = 0;
	for (size_t i = 0; i < MOCK_LINK_MAX_ITEMS; i++) {
		data->item_time[i] = -1;
	}
	data->violations = 0;
	data->violation[0] = '\0';
	data->resets = 0;

	/* A script may start with a URC */
	schedule_next_urc(data);

	k_spin_unlock(&data->script_lock, key);
}

void mock_ctr_lte_link_assert_done(void)
{
	struct ctr_lte_link_data *data = get_data(DEVICE_DT_INST_GET(0));

	int violations;
	char violation[VIOLATION_BUF_SIZE];
	size_t index;
	size_t count;
	const char *next_tx = NULL;
	const char *next_rx = NULL;

	k_spinlock_key_t key = k_spin_lock(&data->script_lock);

	violations = data->violations;
	strcpy(violation, data->violation);
	index = data->items_index;
	count = data->items_count;
	if (index < count) {
		next_tx = data->items[index].tx;
		next_rx = data->items[index].rx;
	}

	k_spin_unlock(&data->script_lock, key);

	zassert_equal(violations, 0, "%d script violation(s), the first: %s", violations,
		      violation);
	zassert_equal(index, count, "script stopped at item %zu of %zu (tx: %s, rx: %s)", index,
		      count, next_tx ? next_tx : "-", next_rx ? next_rx : "-");
}

int mock_ctr_lte_link_reset_count(void)
{
	return atomic_get(&m_reset_count);
}

void mock_ctr_lte_link_drop_ready(int count)
{
	atomic_set(&m_ready_drop, count);
}

void mock_ctr_lte_link_model_subscriptions(bool on)
{
	struct ctr_lte_link_data *data = get_data(DEVICE_DT_INST_GET(0));

	k_spinlock_key_t key = k_spin_lock(&data->script_lock);

	data->model_subscriptions = on;
	data->cereg_subscribed = false;
	data->cscon_subscribed = false;

	k_spin_unlock(&data->script_lock, key);
}

int mock_ctr_lte_link_reset_item(int n)
{
	struct ctr_lte_link_data *data = get_data(DEVICE_DT_INST_GET(0));
	int item = -1;

	k_spinlock_key_t key = k_spin_lock(&data->script_lock);

	if (n >= 0 && n < MIN(data->resets, MOCK_LINK_MAX_RESETS) &&
	    data->wake_up_item[n] == data->reset_item[n]) {
		item = data->reset_item[n];
	}

	k_spin_unlock(&data->script_lock, key);

	return item;
}

int64_t mock_ctr_lte_link_tx_time(size_t index)
{
	struct ctr_lte_link_data *data = get_data(DEVICE_DT_INST_GET(0));
	int64_t time = -1;

	k_spinlock_key_t key = k_spin_lock(&data->script_lock);

	if (index < data->items_count) {
		time = data->item_time[index];
	}

	k_spin_unlock(&data->script_lock, key);

	return time;
}
```

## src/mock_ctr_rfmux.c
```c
/*
 * Copyright (c) 2023 HARDWARIO a.s.
 *
 * SPDX-License-Identifier: LicenseRef-HARDWARIO-5-Clause
 */

/* CHESTER includes */
#include <chester/drivers/ctr_rfmux.h>

/* Zephyr includes */
#include <zephyr/devicetree.h>
#include <zephyr/drivers/gpio.h>
#include <zephyr/kernel.h>
#include <zephyr/logging/log.h>

/* Standard includes */
#include <stdbool.h>
#include <stddef.h>

#define DT_DRV_COMPAT hardwario_ctr_rfmux

LOG_MODULE_REGISTER(ctr_rfmux, CONFIG_CTR_RFMUX_LOG_LEVEL);

struct ctr_rfmux_data {
	const struct device *dev;
	struct k_sem lock;
	bool is_acquired;
};

static inline struct ctr_rfmux_data *get_data(const struct device *dev)
{
	return dev->data;
}

static int ctr_rfmux_acquire_(const struct device *dev)
{
	if (k_is_in_isr()) {
		return -EWOULDBLOCK;
	}

	k_sem_take(&get_data(dev)->lock, K_FOREVER);

	if (get_data(dev)->is_acquired) {
		k_sem_give(&get_data(dev)->lock);
		return -EBUSY;
	}

	get_data(dev)->is_acquired = true;

	k_sem_give(&get_data(dev)->lock);

	return 0;
}

static int ctr_rfmux_release_(const struct device *dev)
{
	if (k_is_in_isr()) {
		return -EWOULDBLOCK;
	}

	k_sem_take(&get_data(dev)->lock, K_FOREVER);

	if (!get_data(dev)->is_acquired) {
		k_sem_give(&get_data(dev)->lock);
		return -EACCES;
	}

	get_data(dev)->is_acquired = false;

	k_sem_give(&get_data(dev)->lock);

	return 0;
}

static int ctr_rfmux_set_interface_(const struct device *dev, enum ctr_rfmux_interface interface)
{

	if (k_is_in_isr()) {
		return -EWOULDBLOCK;
	}

	k_sem_take(&get_data(dev)->lock, K_FOREVER);

	if (!get_data(dev)->is_acquired) {
		k_sem_give(&get_data(dev)->lock);
		return -EACCES;
	}

	k_sem_give(&get_data(dev)->lock);

	return 0;
}

static int ctr_rfmux_set_antenna_(const struct device *dev, enum ctr_rfmux_antenna antenna)
{

	if (k_is_in_isr()) {
		return -EWOULDBLOCK;
	}

	k_sem_take(&get_data(dev)->lock, K_FOREVER);

	if (!get_data(dev)->is_acquired) {
		k_sem_give(&get_data(dev)->lock);
		return -EACCES;
	}

	k_sem_give(&get_data(dev)->lock);

	return 0;
}

static int ctr_rfmux_init(const struct device *dev)
{

	k_sem_give(&get_data(dev)->lock);

	return 0;
}

static const struct ctr_rfmux_driver_api ctr_rfmux_driver_api = {
	.acquire = ctr_rfmux_acquire_,
	.release = ctr_rfmux_release_,
	.set_interface = ctr_rfmux_set_interface_,
	.set_antenna = ctr_rfmux_set_antenna_,
};

#define CTR_RFMUX_INIT(n)                                                                          \
	static struct ctr_rfmux_data inst_##n##_data = {                                           \
		.dev = DEVICE_DT_INST_GET(n),                                                      \
		.lock = Z_SEM_INITIALIZER(inst_##n##_data.lock, 0, 1),                             \
	};                                                                                         \
	DEVICE_DT_INST_DEFINE(n, ctr_rfmux_init, NULL, &inst_##n##_data, NULL, POST_KERNEL,        \
			      CONFIG_KERNEL_INIT_PRIORITY_DEVICE, &ctr_rfmux_driver_api);

DT_INST_FOREACH_STATUS_OKAY(CTR_RFMUX_INIT)
```

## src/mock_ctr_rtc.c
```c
#include <chester/ctr_rtc.h>

static int64_t m_ts = 0;

int ctr_rtc_set_ts(int64_t ts)
{
	m_ts = ts;
	return 0;
}

int ctr_rtc_get_ts(int64_t *ts)
{
	*ts = m_ts;
	return 0;
}
```

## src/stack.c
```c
/*
 * Copyright (c) 2026 HARDWARIO a.s.
 *
 * SPDX-License-Identifier: LicenseRef-HARDWARIO-5-Clause
 */

#include "stack.h"

#include "ctr_lte_v2_state.h"

#include <chester/ctr_lte_v2.h>

/* Zephyr includes */
#include <zephyr/kernel.h>
#include <zephyr/shell/shell.h>
#include <zephyr/shell/shell_dummy.h>
#include <zephyr/ztest.h>

/* Standard includes */
#include <errno.h>
#include <stdbool.h>
#include <stdint.h>
#include <string.h>

/* clang-format off */
static struct mock_link_item m_attach_items[] = {
	ITEMS_PREPARE,
	ITEMS_REGISTER,
};
/* clang-format on */

int stack_attach_index(const char *tx)
{
	for (size_t i = 0; i < ARRAY_SIZE(m_attach_items); i++) {
		if (m_attach_items[i].tx && !strcmp(m_attach_items[i].tx, tx)) {
			return i;
		}
	}

	return -ENOENT;
}

void stack_attach(void)
{
	mock_ctr_lte_link_start(m_attach_items, ARRAY_SIZE(m_attach_items));

	ctr_lte_v2_enable();

	for (int i = 0; i < 60 && strcmp(ctr_lte_v2_get_state(), "open_socket"); i++) {
		k_sleep(K_MSEC(100));
	}
	ASSERT_FSM_STATE("open_socket");

	/* Attached to the network, the socket is not connected yet */
	bool attached = false;
	zassert_ok(ctr_lte_v2_is_attached(&attached));
	zassert_true(attached, "expected attached while the socket connects");
	zassert_equal(ctr_lte_v2_wait_for_connected(K_NO_WAIT), -ETIMEDOUT,
		      "expected not connected while the socket connects");

	int ret = ctr_lte_v2_wait_for_connected(K_MSEC(6000));
	zassert_ok(ret, "ctr_lte_v2_wait_for_connected failed");

	k_sleep(K_MSEC(500));

	ASSERT_FSM_STATE("ready");
	mock_ctr_lte_link_assert_done();
}

void stack_wait_for_state(const char *state, k_timeout_t timeout)
{
	k_timepoint_t end = sys_timepoint_calc(timeout);

	while (strcmp(ctr_lte_v2_get_state(), state) && !sys_timepoint_expired(end)) {
		k_sleep(K_MSEC(10));
	}

	zassert_equal(strcmp(ctr_lte_v2_get_state(), state), 0, "expected state %s but got: %s",
		      state, ctr_lte_v2_get_state());
}

int stack_send_recv(struct ctr_lte_v2_send_recv_param *param, int64_t *elapsed)
{
	int64_t start = k_uptime_get();
	int ret = ctr_lte_v2_send_recv(param);
	*elapsed = k_uptime_get() - start;

	return ret;
}

static K_THREAD_STACK_DEFINE(m_caller_stack, 2048);
static struct k_thread m_caller_thread;
static struct ctr_lte_v2_send_recv_param *m_caller_param;
static int64_t m_caller_elapsed;
static int m_caller_ret;

static void caller_entry(void *p1, void *p2, void *p3)
{
	m_caller_ret = stack_send_recv(m_caller_param, &m_caller_elapsed);
}

/* Call send_recv from a thread of the priority instead of the (cooperative) test thread */
void stack_caller_start(struct ctr_lte_v2_send_recv_param *param, int prio)
{
	m_caller_param = param;

	k_thread_create(&m_caller_thread, m_caller_stack, K_THREAD_STACK_SIZEOF(m_caller_stack),
			caller_entry, NULL, NULL, NULL, prio, 0, K_NO_WAIT);
}

int stack_caller_join(int64_t *elapsed)
{
	zassert_ok(k_thread_join(&m_caller_thread, K_SECONDS(60)));

	*elapsed = m_caller_elapsed;

	return m_caller_ret;
}

void stack_sleep_until(int64_t uptime)
{
	int64_t now = k_uptime_get();

	if (uptime > now) {
		k_sleep(K_MSEC(uptime - now));
	}
}

/* The output of a shell command */
const char *stack_shell_cmd(const char *cmd)
{
	const struct shell *sh = shell_backend_dummy_get_ptr();
	size_t size;

	WAIT_FOR(shell_ready(sh), 20000, k_msleep(1));
	shell_backend_dummy_clear_output(sh);
	int ret = shell_execute_cmd(sh, cmd);
	const char *out = shell_backend_dummy_get_output(sh, &size);
	zassert_ok(ret, "%s failed: %d: %s", cmd, ret, out);

	return out;
}

/* Give a transaction up while the FSM is in a state without IO: the call returns at the deadline,
 * and the state is left alone */
void stack_give_up(const char *state)
{
	struct ctr_lte_v2_send_recv_param param = {
		.send_buf = "Hello world",
		.send_len = 11,
		.send_as_string = true,
		.timeout = K_SECONDS(2),
		.rai = true,
	};

	int64_t elapsed;
	int ret = stack_send_recv(&param, &elapsed);
	zassert_equal(ret, -ETIMEDOUT, "expected -ETIMEDOUT but got: %d", ret);
	zassert_true(elapsed >= 2000 && elapsed <= 2100, "returned %lld ms after the call",
		     elapsed);

	zassert_equal(strcmp(ctr_lte_v2_get_state(), state), 0, "expected state %s but got: %s",
		      state, ctr_lte_v2_get_state());
}

void stack_go_to_sleep(void)
{
	/* clang-format off */
	static struct mock_link_item items[] = {
		ITEMS_SLEEP(100),
	};
	/* clang-format on */

	mock_ctr_lte_link_start(items, ARRAY_SIZE(items));

	stack_wait_for_state("sleep", K_SECONDS(2));
	/* Past the pause after AT#XSLEEP */
	k_sleep(K_MSEC(500));
	mock_ctr_lte_link_assert_done();
}
```

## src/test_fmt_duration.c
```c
/*
 * Copyright (c) 2026 HARDWARIO a.s.
 *
 * SPDX-License-Identifier: LicenseRef-HARDWARIO-5-Clause
 */

/* CHESTER includes */
#include <chester/ctr_util.h>

/* Zephyr includes */
#include <zephyr/kernel.h>
#include <zephyr/ztest.h>

/* Standard includes */
#include <errno.h>
#include <stdint.h>

static void expect(uint32_t sec, const char *exp)
{
	char buf[24];

	zassert_ok(ctr_util_fmt_duration(sec, buf, sizeof(buf)));
	zassert_str_equal(buf, exp, "%u s -> '%s'", sec, buf);
}

ZTEST(util_fmt_duration, test_units)
{
	expect(0, "0s");
	expect(45, "45s");
	expect(2210, "36m 50s");
	expect(3723, "1h 02m 03s");
	expect(93784, "1d 02h 03m 04s");
	expect(UINT32_MAX, "49710d 06h 28m 15s");
}

ZTEST(util_fmt_duration, test_too_small)
{
	char buf[4];

	zassert_equal(ctr_util_fmt_duration(2210, buf, sizeof(buf)), -ENOSPC);
}

ZTEST_SUITE(util_fmt_duration, NULL, NULL, NULL, NULL, NULL);
```
